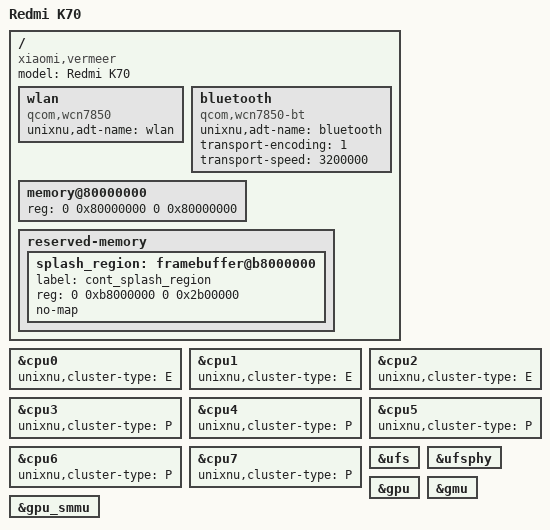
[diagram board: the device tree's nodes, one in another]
// SPDX-License-Identifier: BSD-3-Clause
// Redmi K70 (vermeer, SM8550). Board values measured on the device:
// stock ABL device tree (/sys/firmware/fdt, HyperOS OS3.0.307.0.WNKCNXM).
/dts-v1/;
/include/ "sm8550.dtsi"

/ {
    model = "Redmi K70";
    compatible = "xiaomi,vermeer", "qcom,sm8550";

    // FastConnect 7800 (WCN7850), the connectivity pair of SM8550; the WiFi
    // probe fills local-mac-address at runtime.
    wlan {
        compatible = "qcom,wcn7850";
        unixnu,adt-name = "wlan";
        status = "okay";
    };

    bluetooth {
        device_type = "bluetooth";
        compatible = "qcom,wcn7850-bt";
        unixnu,adt-name = "bluetooth";
        transport-encoding = <1>;
        transport-speed = <3200000>;
        status = "okay";
    };

    // 16 GiB device. The stock ABL map starts the usable range at 0x80000000 with carveouts.
    //
    // 0x80000000 was tried and made no difference: with 0x56000000 (ending 0xd6000000) the
    // fault registers were identical (ELR 0xc258ce10, FAR 0xe8004000, x1 = x2 = 0x100000000),
    // so the early fault does not depend on this declaration. It is back to the reference
    // board's value, which is what the firmware's memory tables were built against.
    memory@80000000 {
        device_type = "memory";
        reg = <0 0x80000000 0 0x80000000>;
    };

    reserved-memory {
        #address-cells = <2>;
        #size-cells = <2>;
        ranges;
        // Continuous splash region, identical to the value measured in the
        // stock tree (0xb8000000, 0x2b00000).
        splash_region: framebuffer@b8000000 {
            label = "cont_splash_region";
            reg = <0 0xb8000000 0 0x2b00000>;
            no-map;
        };
    };
};

// Stock topology: cpu0-2 Cortex-A510, cpu3-4 A715, cpu5-6 A710, cpu7 X3.
&cpu0 { unixnu,cluster-type = "E"; };
&cpu1 { unixnu,cluster-type = "E"; };
&cpu2 { unixnu,cluster-type = "E"; };
&cpu3 { unixnu,cluster-type = "P"; };
&cpu4 { unixnu,cluster-type = "P"; };
&cpu5 { unixnu,cluster-type = "P"; };
&cpu6 { unixnu,cluster-type = "P"; };
&cpu7 { unixnu,cluster-type = "P"; };
// UFS behind the standard SM8550 controller; the storage driver archive is
// selected by its bring-up stage. GPU nodes stay exported for Adreno740.
//
// GMU register windows differ from the shared SoC description: the stock vermeer
// device tree describes qcom,gmu@3d69000 as <0x3d68000 0x37000>, <0xb280000
// 0x10000>, <0x3d40000 0x10000> with the same end address as the shared
// gmu@3d6a000 window, while the rscc window starts at 0x3d40000 instead of
// 0x3d50000. No GPU driver is selected yet, so the shared node is left in place
// and this difference is unresolved until the gpu stage; see porting.toml.
&ufs { status = "okay"; };
&ufsphy { status = "okay"; };
&gpu { status = "okay"; };
&gmu { status = "okay"; };
&gpu_smmu { status = "okay"; };
